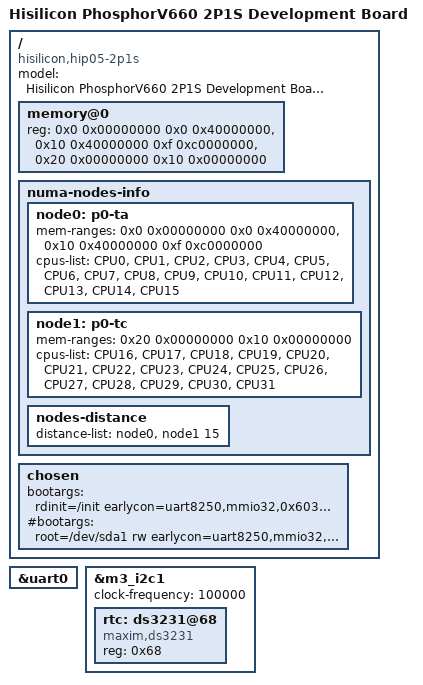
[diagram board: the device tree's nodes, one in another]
/**
 * dts file for Hisilicon PhosphorV660 2P1S Board
 *
 * Copyright (C) 2014,2015 Hisilicon Ltd.
 *
 * This program is free software; you can redistribute it and/or modify
 * it under the terms of the GNU General Public License version 2 as
 * publishhed by the Free Software Foundation.
 *
 */

/dts-v1/;

/include/ "hip05-2p1s.dtsi"
/include/ "hip05-2p1s-pcie.dtsi"

/ {
	model = "Hisilicon PhosphorV660 2P1S Development Board";
	compatible = "hisilicon,hip05-2p1s", "hisilicon,hisi-pv660";

	memory@0 {
		device_type = "memory";
		reg = <0x0 0x00000000 0x0 0x40000000>,
		      <0x10 0x40000000 0xf 0xc0000000>,
		      <0x20 0x00000000 0x10 0x00000000>;
	};

	numa-nodes-info {
		node0: p0-ta {
			mem-ranges = <0x0 0x00000000 0x0 0x40000000>, <0x10 0x40000000 0xf 0xc0000000>;
			cpus-list = <&CPU0 &CPU1 &CPU2 &CPU3>,
				    <&CPU4 &CPU5 &CPU6 &CPU7>,
				    <&CPU8 &CPU9 &CPU10 &CPU11>,
				    <&CPU12 &CPU13 &CPU14 &CPU15>;
		};

		node1: p0-tc {
			mem-ranges = <0x20 0x00000000 0x10 0x00000000>;
			cpus-list = <&CPU16 &CPU17 &CPU18 &CPU19>,
				    <&CPU20 &CPU21 &CPU22 &CPU23>,
				    <&CPU24 &CPU25 &CPU26 &CPU27>,
				    <&CPU28 &CPU29 &CPU30 &CPU31>;
		};

		nodes-distance {
			distance-list = <&node0 &node1 15>;
		};
	};

	/include/ "hip05-2p1s-hns.dtsi"

	chosen {
		bootargs = "rdinit=/init earlycon=uart8250,mmio32,0x60300000 pci=pcie_bus_perf console=ttyS0,115200 initrd=0x7000000,350M";
		#bootargs = "root=/dev/sda1 rw earlycon=uart8250,mmio32,0x60300000 console=ttyS0,115200 pci=pcie_bus_perf";
	};

};

&uart0 {
	status = "okay";
};

&m3_i2c1 {
	clock-frequency = <100000>;
	status = "okay";

	rtc: ds3231@68 {
		compatible = "maxim,ds3231";
		reg = <0x68>;
	};
};
